VERSION ""

NS_ :

BS_:

BU_:

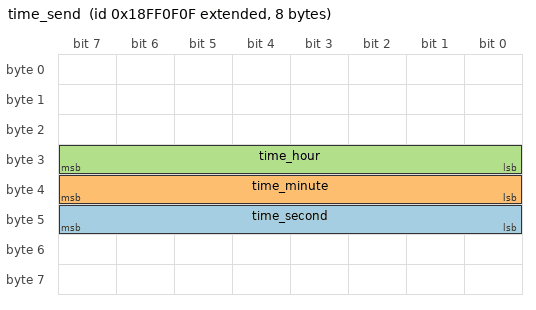
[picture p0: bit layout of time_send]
BO_ 2566852367 time_send: 8 Vector__XXX
 SG_ time_second : 40|8@1+ (1,0) [0|0] "" Vector__XXX
 SG_ time_minute : 32|8@1+ (1,0) [0|0] "" Vector__XXX
 SG_ time_hour : 24|8@1+ (1,0) [0|0] "" Vector__XXX

BO_ 2550853416 BUS_OPEN: 8 Vector__XXX
 SG_ rear_door_state : 4|2@1+ (1,0) [0|0] "" Vector__XXX
 SG_ Front_door_state : 2|2@1+ (1,0) [0|0] "" Vector__XXX

BA_DEF_  "BusType" STRING ;
BA_DEF_DEF_  "BusType" "CAN";
